# STM32H7P5 register map
File version: 0.1
CPU: CM7 r1p2, little endian, MPU, FPU, 4 interrupt priority bits
Registers are 32-bit, read-write, reset 0x0 unless marked. A register's access mark holds for its fields unless they carry their own. Offsets are from the block's base; [hi:lo] are bit positions; {n}, {i} and the like mark numbered series; 'fields as' and 'values as' point back to an identical list.

## DBGMCU — DBGMCU address block description
Base 0x5C001000
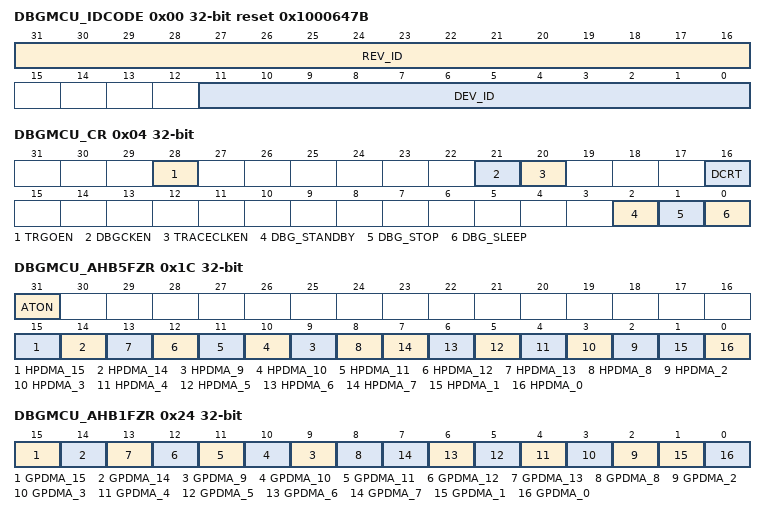
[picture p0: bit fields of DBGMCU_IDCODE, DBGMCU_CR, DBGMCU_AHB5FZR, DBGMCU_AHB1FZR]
0x00 DBGMCU_IDCODE ro reset 0x1000647B — DBGMCU identity code register
  [31:16] REV_ID — 0x1000 = revision A
  [11:0] DEV_ID — Device ID
    0x47B=STM32H7Pxx
0x04 DBGMCU_CR — DBGMCU configuration register
  [28] TRGOEN — External trigger output enable
    0=Input - TRGIO is connected to TRGIN; 1=Output - TRGIO is connected to TRGOUT
  [21] DBGCKEN — Debug clock enable
    0=Disabled - debug components are disabled and their clocks gated; 1=Enabled - debug components are clocked whenever the corresponding domain clock (CK_HCLK) is active
  [20] TRACECLKEN — Trace port clock enable.
    0=Disabled - traceclkin is disabled; 1=Enabled - traceclkin is active
  [16] DCRT — Debug credentials reset type
    0=System reset; 1=Power reset
  [2] DBG_STANDBY — Debug in Standby mode enable
    0=Normal operation - all clocks are disabled and the core powered down automatically in Standby mode; 1=Automatic clock stop/power-down disabled - all active clocks and oscillators continue to run during Standby mode, and the core supply is maintained, allowing full debug capability. On exit from Standby mode, a core reset is performed.
  [1] DBG_STOP — Debug in Stop mode enable
    0=Normal operation - all clocks are disabled automatically in Stop mode; 1=Automatic clock stop disabled - all active clocks and oscillators continue to run during Stop mode, allowing full debug capability. On exit from Stop mode, the clock settings are set to the Stop mode exit state.
  [0] DBG_SLEEP — Debug in Sleep mode enable
    0=Normal operation - the processor clock is stopped automatically in Sleep mode; 1=Automatic clock stop disabled - processor clock continues to run, allowing full debug capability
0x1C DBGMCU_AHB5FZR — DBGMCU AHB5 peripheral freeze register
  [31] ATON — ATON stop in debug
    0=Normal operation. ATON continues to operate while the CPU is in debug mode.; 1=Stop in debug. ATON is frozen while the CPU is in debug mode.
  [15] HPDMA_15 — HPDMA channel 15 stop in debug
    0=Normal operation. HPDMA channel 15 continues to operate while the CPU is in debug mode.; 1=Stop in debug. HPDMA channel 15 is frozen while the CPU is in debug mode.
  [14] HPDMA_14 — HPDMA channel 14 stop in debug
    0=Normal operation. HPDMA channel 14 continues to operate while the CPU is in debug mode.; 1=Stop in debug. HPDMA channel 14 is frozen while the CPU s in debug mode.
  [n] HPDMA_{n} (n=9..13) — HPDMA channel {n} stop in debug
    0=Normal operation. HPDMA channel {n} continues to operate while the CPU is in debug mode.; 1=Stop in debug. HPDMA channel {n} is frozen while the CPU is in debug mode.
  [8] HPDMA_8 — HPDMA channel 8 stop in debug
    0=Normal operation. HPDMA channel 8 continues to operate while the CPU is in debug mode.; 1=Stop in debug. HPDMA channel _ is frozen while the CPU is in debug mode.
  [n] HPDMA_{n} (n=2..7) — HPDMA channel {n} stop in debug
    values as HPDMA_9
  [1] HPDMA_1 — HPDMA channel 1 stop in debug
    0=Normal operation. HPDMA channel 1continues to operate while the CPU is in debug mode.; 1=Stop in debug. HPDMA channel 1 is frozen while the CPU is in debug mode.
  [0] HPDMA_0 — HPDMA channel 0 stop in debug
    0=Normal operation. HPDMA channel 0 continues to operate while the CPU is in debug mode.; 1=Stop in debug. HPDMA channel 0 is frozen while the CPU is in debug mode.
0x24 DBGMCU_AHB1FZR — DBGMCU AHB1 peripheral freeze register
  [15] GPDMA_15 — GPDMA channel 15 stop in debug
    0=Normal operation. GPDMA channel 15 continues to operate while the CPU is in debug mode.; 1=Stop in debug. GPDMA channel 15 is frozen while the CPU is in debug mode.
  [14] GPDMA_14 — GPDMA channel 14 stop in debug
    0=Normal operation. GPDMA channel 14 continues to operate while the CPU is in debug mode.; 1=Stop in debug. GPDMA channel 14 is frozen while the CPU s in debug mode.
  [n] GPDMA_{n} (n=9..13) — GPDMA channel {n} stop in debug
    0=Normal operation. GPDMA channel {n} continues to operate while the CPU is in debug mode.; 1=Stop in debug. GPDMA channel {n} is frozen while the CPU is in debug mode.
  [8] GPDMA_8 — GPDMA channel 8 stop in debug
    0=Normal operation. GPDMA channel 8 continues to operate while the CPU is in debug mode.; 1=Stop in debug. GPDMA channel _ is frozen while the CPU is in debug mode.
  [n] GPDMA_{n} (n=2..7) — GPDMA channel {n} stop in debug
    values as GPDMA_9
  [1] GPDMA_1 — GPDMA channel 1 stop in debug
    0=Normal operation. GPDMA channel 1continues to operate while the CPU is in debug mode.; 1=Stop in debug. GPDMA channel 1 is frozen while the CPU is in debug mode.
  [0] GPDMA_0 — GPDMA channel 0 stop in debug
    0=Normal operation. GPDMA channel 0 continues to operate while the CPU is in debug mode.; 1=Stop in debug. GPDMA channel 0 is frozen while the CPU is in debug mode.
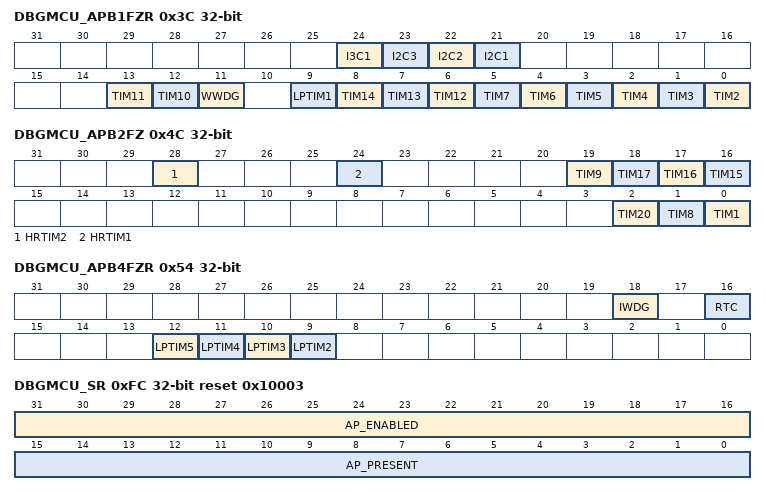
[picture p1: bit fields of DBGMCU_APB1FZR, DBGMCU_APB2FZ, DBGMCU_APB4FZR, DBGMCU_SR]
0x3C DBGMCU_APB1FZR — DBGMCU APB1 peripheral freeze register
  [24] I3C1 — I3C1 SMBUS timeout stop in debug
    0=Normal operation - I3C1 SMBUS timeout continues operating while the core is in Debug mode; 1=Stop in debug - I3C1 SMBUS timeout is frozen while Cortex-M7 is in Debug mode
  [23] I2C3 — I2C3 SMBUS timeout stop in debug
    0=Normal operation - I2C3 SMBUS timeout continues operating while the core is in Debug mode; 1=Stop in debug - I2C3 SMBUS timeout is frozen while Cortex-M7 is in Debug mode
  [22] I2C2 — I2C2 SMBUS timeout stop in debug
    0=Normal operation - I2C2 SMBUS timeout continues operating while the core is in Debug mode; 1=Stop in debug - I2C2 SMBUS timeout is frozen while Cortex-M7 is in Debug mode
  [21] I2C1 — I2C1 SMBUS timeout stop in debug
    0=Normal operation - I2C1 SMBUS timeout continues operating while the core is in Debug mode; 1=Stop in debug - I2C1 SMBUS timeout is frozen while the core is in Debug mode
  [13] TIM11 — TIM11 stop in debug
    0=Normal operation - TIM11 continues operating while the core is in Debug mode; 1=Stop in debug - TIM11 is frozen while Cortex-M7 is in Debug mode
  [12] TIM10 — TIM10 stop in debug
    0=Normal operation - TIM10 continues operating while the core is in Debug mode; 1=Stop in debug - TIM10 is frozen while Cortex-M7 is in Debug mode
  [11] WWDG — WWDG stop in debug
    0=Normal operation - WWDG continues to operate while the Cortex-M7 is in Debug mode; 1=Stop in debug - WWDG is frozen while the Cortex-M7 is in Debug mode
  [9] LPTIM1 — LPTIM1 stop in debug
    0=Normal operation - LPTIM1 continues operating while the core is in Debug mode; 1=Stop in debug - LPTIM1 is frozen while Cortex-M7 is in Debug mode
  [8] TIM14 — TIM14 stop in debug
    0=Normal operation - TIM14 continues operating while the core is in Debug mode; 1=Stop in debug - TIM14 is frozen while Cortex-M7 is in Debug mode
  [7] TIM13 — TIM13 stop in debug
    0=Normal operation - TIM13 continues operating while the core is in Debug mode; 1=Stop in debug - TIM13 is frozen while Cortex-M7 is in Debug mode
  [6] TIM12 — TIM12 stop in debug
    0=Normal operation - TIM12 continues operatinge while the core is in Debug mode; 1=Stop in debug - TIM12 is frozen while Cortex-M7 is in Debug mode
  [5] TIM7 — TIM7 stop in debug
    0=Normal operation - TIM7 continues operatinge while the core is in Debug mode; 1=Stop in debug - TIM7 is frozen while Cortex-M7 is in Debug mode
  [n-2] TIM{n} (n=2..6) — TIM{n} stop in debug
    0=Normal operation - TIM{n} continues operating while the core is in Debug mode; 1=Stop in debug - TIM{n} is frozen while Cortex-M7 is in Debug mode
0x4C DBGMCU_APB2FZ — DBGMCU APB2 peripheral freeze register
  [28] HRTIM2 — HRTIM2 stop in debug
    0=Normal operation - HRTIM2 continues operating while the core is in Debug mode; 1=Stop in debug - HRTIM2 is frozen and HRTIM2 outputs are held in a safe state while Cortex-M7 is in Debug mode
  [24] HRTIM1 — HRTIM1 stop in debug
    0=Normal operation - HRTIM1 continues operating while the core is in Debug mode; 1=Stop in debug - HRTIM1 is frozen and HRTIM1 outputs are held in a safe state while Cortex-M7 is in Debug mode
  [19] TIM9 — TIM9 stop in debug
    0=Normal operation - TIM9 continues operating while the core is in Debug mode; 1=Stop in debug - TIM9 is frozen and TIM9 outputs are disabled while Cortex-M7 is in Debug mode
  [18] TIM17 — TIM17 stop in debug
    0=Normal operation - TIM17 continues operating while the core is in Debug mode; 1=Stop in debug - TIM17 is frozen and TIM17 outputs are disabled while Cortex-M7 is in Debug mode
  [17] TIM16 — TIM16 stop in debug
    0=Normal operation - TIM16 continues operating while the core is in Debug mode; 1=Stop in debug - TIM16 is frozen and TIM16 outputs are disabled while Cortex-M7 is in Debug mode
  [16] TIM15 — TIM15 stop in debug
    0=Normal operation - TIM15 continues operating while the core is in Debug mode; 1=Stop in debug - TIM15 is frozen and TIM15 outputs are disabled while Cortex-M7 is in Debug mode
  [2] TIM20 — TIM20/PWM20 stop in debug
    0=Normal operation - TIM20 continues operating while the core is in Debug mode; 1=Stop in debug - TIM20 is frozen and TIM20 outputs are disabled while Cortex-M7 is in Debug mode
  [1] TIM8 — TIM8/PWM8 stop in debug
    0=Normal operation - TIM8 continues operating while the core is in Debug mode; 1=Stop in debug - TIM8 is frozen and TIM8 outputs are disabled while Cortex-M7 is in Debug mode
  [0] TIM1 — TIM1/PWM1 stop in debug
    0=Normal operation - TIM1 continues operating while the core is in Debug mode; 1=Stop in debug - TIM1 is frozen and TIM1 outputs are disabled while Cortex-M7 is in Debug mode
0x54 DBGMCU_APB4FZR — DBGMCU APB4 peripheral freeze register
  [18] IWDG — Independent watchdog for stop in debug
    0=Normal operation - watchdog continues counting while the core is in Debug mode; 1=Stop in debug - watchdog is frozen while Cortex-M7 is in Debug mode
  [16] RTC — RTC stop in debug
    0=Normal operation - RTC continues operating while the core is in Debug mode; 1=Stop in debug - RTC is frozen while Cortex-M7 is in Debug mode
  [12] LPTIM5 — LPTIM5 stop in debug
    0=Normal operation - LPTIM5 continues operating while the core is in Debug mode; 1=Stop in debug - LPTIM5 is frozen while Cortex-M7 is in Debug mode
  [11] LPTIM4 — LPTIM4 stop in debug
    0=Normal operation - LPTIM4 continues operating while the core is in Debug mode; 1=Stop in debug - LPTIM4 is frozen while Cortex-M7 is in Debug mode
  [10] LPTIM3 — LPTIM3 stop in debug
    0=Normal operation - LPTIM2 continues operating while the core is in Debug mode; 1=Stop in debug - LPTIM2 is frozen while Cortex-M7 is in Debug mode
  [9] LPTIM2 — LPTIM2 stop in debug
    values as LPTIM3
0x80 DBGMCU_EDBGRQ — DBGMCU EDBGRQ input control
  [0] DBG_CPU — Drives the CPU external debug request (EDBGRQ) signal. This signal can be used to halt the CPU in debug on a system reset, instead of writing to the DEMCR.VC_CORERESET bit in the CPU
    0=External debug request de-asserted; 1=The external debug request, EDBGRQ, is asserted when the system reset is active and remains asserted until the cpu is Halted
0xFC DBGMCU_SR ro reset 0x10003 — DBGMCU status register
  [31:16] AP_ENABLED — Bit n identifies whether access port AP n is open (can be accessed via the debug port) or locked (debug access to the AP is blocked)
  [15:0] AP_PRESENT — Bit n identifies whether access port AP n is present in the device
0x100 DBGMCU_DBG_AUTH_HOST reset not defined — DBGMCU debug authentication mailbox host register
  [31:0] MESSAGE — Debug host to device mailbox message.
0x104 DBGMCU_DBG_AUTH_DEVICE reset not defined — DBGMCU debug authentication mailbox device register
  [31:0] MESSAGE — Device to debug host mailbox message.
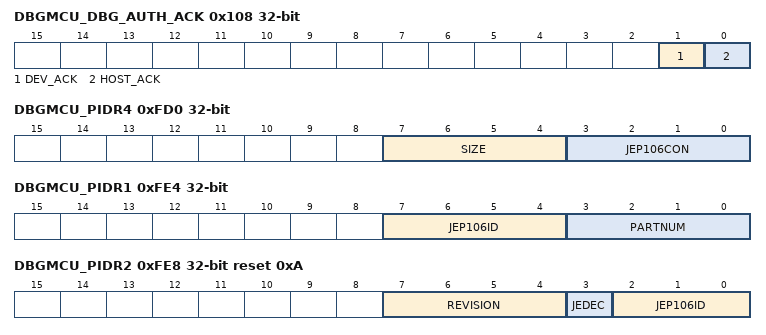
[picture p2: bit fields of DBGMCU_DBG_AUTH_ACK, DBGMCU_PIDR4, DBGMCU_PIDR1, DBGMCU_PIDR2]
0x108 DBGMCU_DBG_AUTH_ACK — DBGMCU debug authentication mailbox acknowledge register
  [1] DEV_ACK — Device to device acknowledge
  [0] HOST_ACK — Host to device acknowledge
0xFD0 DBGMCU_PIDR4 ro — DBGMCU peripheral identity register 4
  [7:4] SIZE — Register file size
    0=Register file occupies a single 4 Kbyte region
  [3:0] JEP106CON — JEP106 continuation code
    0=STMicroelectronics JEDEC code
0xFE0 DBGMCU_PIDR0 ro — DBGMCU peripheral identity register 0
  [7:0] PARTNUM — Part number field, bits [7:0]
    0=DBGMCU
0xFE4 DBGMCU_PIDR1 ro — DBGMCU peripheral identity register 1
  [7:4] JEP106ID — JEP106 identity code field, bits [3:0]
    0=STMicroelectronics JEDEC code
  [3:0] PARTNUM — Part number field, bits [11:8]
    0=DBGMCU
0xFE8 DBGMCU_PIDR2 ro reset 0xA — DBGMCU peripheral identity register 2
  [7:4] REVISION — Component revision number
    0=Rev 0
  [3] JEDEC — JEDEC assigned value
    1=Designer ID specified by JEDEC
  [2:0] JEP106ID — JEP106 identity code field, bits [6:4]
    2=STMicroelectronics JEDEC code
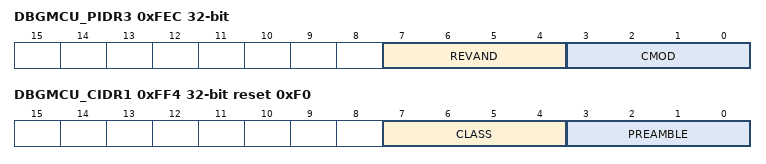
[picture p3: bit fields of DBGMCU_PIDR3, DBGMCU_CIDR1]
0xFEC DBGMCU_PIDR3 ro — DBGMCU peripheral identity register 3
  [7:4] REVAND — Metal fix version
    0=No metal fix
  [3:0] CMOD — Customer modified
    0=No customer modifications
0xFF0 DBGMCU_CIDR0 ro reset 0xD — DBGMCU component identity register
  [7:0] PREAMBLE — Component ID field, bits [7:0]
    13=Common ID value
0xFF4 DBGMCU_CIDR1 ro reset 0xF0 — DBGMCU component identity register
  [7:4] CLASS — Component ID field, bits [15:12] - component class
    15=System component with non-standard register layout
  [3:0] PREAMBLE — Component ID field, bits [11:8]
    0=Common ID value
0xFF8 DBGMCU_CIDR2 ro reset 0x5 — DBGMCU component identity register
  [7:0] PREAMBLE — Component ID field, bits [23:16]
    5=Common ID value
0xFFC DBGMCU_CIDR3 ro reset 0xB1 — DBGMCU component identity register
  [7:0] PREAMBLE — Component ID field, bits [31:24]
    177=Common ID value
